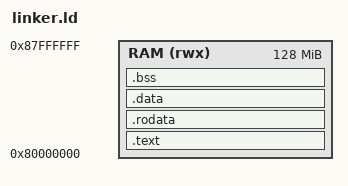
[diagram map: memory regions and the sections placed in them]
ENTRY(_start)

MEMORY {
    RAM (rwx) : ORIGIN = 0x80000000, LENGTH = 128M
}

SECTIONS {
    .text : {
        KEEP(*(.text.init))
        *(.text .text.*)
    } > RAM

    .rodata : { *(.rodata .rodata.*) } > RAM
    .data : { *(.data .data.*) } > RAM
    .bss : {
        _bss_start = .;
        *(.bss .bss.*)
        *(COMMON)
        _bss_end = .;
    } > RAM

    . = ALIGN(16);
    . += 0x4000;
    _stack_top = .;
}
